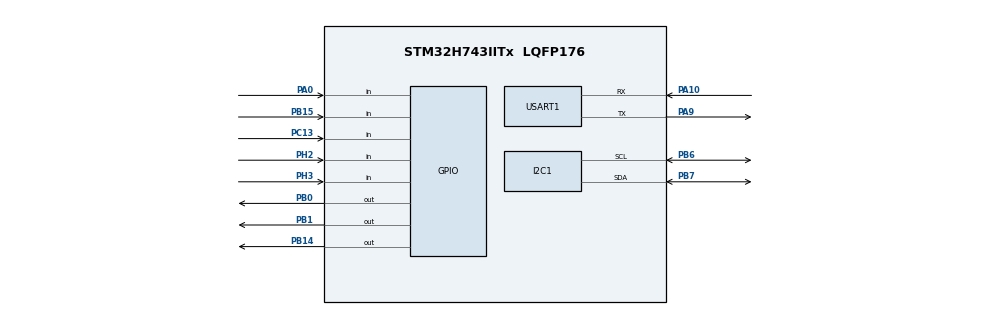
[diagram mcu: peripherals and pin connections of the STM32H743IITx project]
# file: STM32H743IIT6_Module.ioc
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Dma.Request0=USART1_RX
Dma.USART1_RX.0.Direction=DMA_PERIPH_TO_MEMORY
Dma.USART1_RX.0.EventEnable=DISABLE
Dma.USART1_RX.0.FIFOMode=DMA_FIFOMODE_DISABLE
Dma.USART1_RX.0.Instance=DMA1_Stream0
Dma.USART1_RX.0.MemDataAlignment=DMA_MDATAALIGN_BYTE
Dma.USART1_RX.0.MemInc=DMA_MINC_ENABLE
Dma.USART1_RX.0.Mode=DMA_NORMAL
Dma.USART1_RX.0.PeriphDataAlignment=DMA_PDATAALIGN_BYTE
Dma.USART1_RX.0.PeriphInc=DMA_PINC_DISABLE
Dma.USART1_RX.0.Polarity=HAL_DMAMUX_REQ_GEN_RISING
Dma.USART1_RX.0.Priority=DMA_PRIORITY_LOW
Dma.USART1_RX.0.RequestNumber=1
Dma.USART1_RX.0.SignalID=NONE
Dma.USART1_RX.0.SyncEnable=DISABLE
Dma.USART1_RX.0.SyncPolarity=HAL_DMAMUX_SYNC_NO_EVENT
Dma.USART1_RX.0.SyncRequestNumber=1
Dma.USART1_RX.0.SyncSignalID=NONE
I2C1.Timing=0x307075B1
Mcu.Family=STM32H7
Mcu.Name=STM32H743IITx
Mcu.Package=LQFP176
NVIC.DMA1_Stream0_IRQn=true\:0\:0\:false\:false\:true\:false\:true\:true
NVIC.PriorityGroup=NVIC_PRIORITYGROUP_4
NVIC.TIM6_DAC_IRQn=true\:0\:0\:false\:false\:true\:true\:true\:true
NVIC.USART1_IRQn=true\:0\:0\:false\:false\:true\:true\:true\:true
PA0.GPIO_PuPd=GPIO_PULLDOWN
PA0.Signal=GPIO_Input
PA10.Mode=Asynchronous
PA10.Signal=USART1_RX
PA9.Mode=Asynchronous
PA9.Signal=USART1_TX
PB0.Signal=GPIO_Output
PB1.Signal=GPIO_Output
PB14.GPIO_PuPd=GPIO_PULLDOWN
PB14.Signal=GPIO_Output
PB15.GPIO_PuPd=GPIO_PULLDOWN
PB15.Signal=GPIO_Input
PB6.Mode=I2C
PB6.Signal=I2C1_SCL
PB7.Mode=I2C
PB7.Signal=I2C1_SDA
PC13.GPIO_PuPd=GPIO_PULLUP
PC13.Signal=GPIO_Input
PC14-OSC32_IN\ (OSC32_IN).Mode=LSE-External-Oscillator
PC14-OSC32_IN\ (OSC32_IN).Signal=RCC_OSC32_IN
PC15-OSC32_OUT\ (OSC32_OUT).Mode=LSE-External-Oscillator
PC15-OSC32_OUT\ (OSC32_OUT).Signal=RCC_OSC32_OUT
PH0-OSC_IN\ (PH0).Mode=HSE-External-Oscillator
PH0-OSC_IN\ (PH0).Signal=RCC_OSC_IN
PH1-OSC_OUT\ (PH1).Mode=HSE-External-Oscillator
PH1-OSC_OUT\ (PH1).Signal=RCC_OSC_OUT
PH2.GPIO_PuPd=GPIO_PULLUP
PH2.Signal=GPIO_Input
PH3.GPIO_PuPd=GPIO_PULLUP
PH3.Signal=GPIO_Input
ProjectManager.HeapSize=0x200
ProjectManager.StackSize=0x400
ProjectManager.TargetToolchain=MDK-ARM V5.32
RCC.ADCFreq_Value=129000000
RCC.APB1Freq_Value=120000000
RCC.APB2Freq_Value=120000000
RCC.APB3Freq_Value=120000000
RCC.APB4Freq_Value=120000000
RCC.CortexFreq_Value=480000000
RCC.D1PPRE=RCC_APB3_DIV2
RCC.D2PPRE1=RCC_APB1_DIV2
RCC.D2PPRE2=RCC_APB2_DIV2
RCC.D3PPRE=RCC_APB4_DIV2
RCC.DIVM1=4
RCC.DIVN1=60
RCC.HCLKFreq_Value=240000000
RCC.HPRE=RCC_HCLK_DIV2
RCC.HSE_VALUE=25000000
RCC.PLL2FRACN=0
RCC.PLL3FRACN=0
RCC.PLLFRACN=0
RCC.PWR_Regulator_Voltage_Scale=PWR_REGULATOR_VOLTAGE_SCALE0
RCC.SYSCLKFreq_VALUE=480000000
RCC.SYSCLKSource=RCC_SYSCLKSOURCE_PLLCLK
RCC.USBFreq_Value=480000000
TIM6.AutoReloadPreload=TIM_AUTORELOAD_PRELOAD_ENABLE
TIM6.Period=100
TIM6.Prescaler=2400
TIM7.AutoReloadPreload=TIM_AUTORELOAD_PRELOAD_DISABLE
TIM7.Period=24000-1
TIM7.Prescaler=10000-1
USART1.VirtualMode-Asynchronous=VM_ASYNC
VP_MEMORYMAP_VS_MEMORYMAP.Mode=CurAppReg
VP_TIM6_VS_ClockSourceINT.Mode=Enable_Timer
VP_TIM7_VS_ClockSourceINT.Mode=Enable_Timer
board=custom

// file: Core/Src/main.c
/* USER CODE BEGIN Header */
/**
  ******************************************************************************
  * @file           : main.c
  * @brief          : Main program body
  ******************************************************************************
  * @attention
  *
  * <h2><center>&copy; Copyright (c) 2026 STMicroelectronics.
  * All rights reserved.</center></h2>
  *
  * This software component is licensed by ST under BSD 3-Clause license,
  * the "License"; You may not use this file except in compliance with the
  * License. You may obtain a copy of the License at:
  *                        opensource.org/licenses/BSD-3-Clause
  *
  ******************************************************************************
  */
/* USER CODE END Header */
#include "main.h"
#include "dma.h"
#include "i2c.h"
#include "tim.h"
#include "usart.h"
#include "gpio.h"

/* USER CODE BEGIN Includes */
#include "bsp.h"
/* USER CODE END Includes */

void SystemClock_Config(void);

int main(void)
{

  /* MCU Configuration--------------------------------------------------------*/

  /* Reset of all peripherals, Initializes the Flash interface and the Systick. */
  HAL_Init();

  /* Configure the system clock */
  SystemClock_Config();

  /* Initialize all configured peripherals */
  MX_GPIO_Init();
  MX_DMA_Init();
  MX_TIM6_Init();
  MX_USART1_UART_Init();
  MX_I2C1_Init();
  MX_TIM7_Init();
  /* USER CODE BEGIN 2 */
  Sys_Init();
  /* USER CODE END 2 */

  /* Infinite loop */
  while (1)
  {

    /* USER CODE BEGIN 3 */
    Sys_Run();
  }
  /* USER CODE END 3 */
}

void SystemClock_Config(void)
{
  RCC_OscInitTypeDef RCC_OscInitStruct = {0};
  RCC_ClkInitTypeDef RCC_ClkInitStruct = {0};

  /** Supply configuration update enable
  */
  HAL_PWREx_ConfigSupply(PWR_LDO_SUPPLY);

  /** Configure the main internal regulator output voltage
  */
  __HAL_PWR_VOLTAGESCALING_CONFIG(PWR_REGULATOR_VOLTAGE_SCALE0);

  while(!__HAL_PWR_GET_FLAG(PWR_FLAG_VOSRDY)) {}

  /** Initializes the RCC Oscillators according to the specified parameters
  * in the RCC_OscInitTypeDef structure.
  */
  RCC_OscInitStruct.OscillatorType = RCC_OSCILLATORTYPE_HSI;
  RCC_OscInitStruct.HSIState = RCC_HSI_DIV1;
  RCC_OscInitStruct.HSICalibrationValue = RCC_HSICALIBRATION_DEFAULT;
  RCC_OscInitStruct.PLL.PLLState = RCC_PLL_ON;
  RCC_OscInitStruct.PLL.PLLSource = RCC_PLLSOURCE_HSI;
  RCC_OscInitStruct.PLL.PLLM = 4;
  RCC_OscInitStruct.PLL.PLLN = 60;
  RCC_OscInitStruct.PLL.PLLP = 2;
  RCC_OscInitStruct.PLL.PLLQ = 2;
  RCC_OscInitStruct.PLL.PLLR = 2;
  RCC_OscInitStruct.PLL.PLLRGE = RCC_PLL1VCIRANGE_3;
  RCC_OscInitStruct.PLL.PLLVCOSEL = RCC_PLL1VCOWIDE;
  RCC_OscInitStruct.PLL.PLLFRACN = 0;
  if (HAL_RCC_OscConfig(&RCC_OscInitStruct) != HAL_OK)
  {
    Error_Handler();
  }

  /** Initializes the CPU, AHB and APB buses clocks
  */
  RCC_ClkInitStruct.ClockType = RCC_CLOCKTYPE_HCLK|RCC_CLOCKTYPE_SYSCLK
                              |RCC_CLOCKTYPE_PCLK1|RCC_CLOCKTYPE_PCLK2
                              |RCC_CLOCKTYPE_D3PCLK1|RCC_CLOCKTYPE_D1PCLK1;
  RCC_ClkInitStruct.SYSCLKSource = RCC_SYSCLKSOURCE_PLLCLK;
  RCC_ClkInitStruct.SYSCLKDivider = RCC_SYSCLK_DIV1;
  RCC_ClkInitStruct.AHBCLKDivider = RCC_HCLK_DIV2;
  RCC_ClkInitStruct.APB3CLKDivider = RCC_APB3_DIV2;
  RCC_ClkInitStruct.APB1CLKDivider = RCC_APB1_DIV2;
  RCC_ClkInitStruct.APB2CLKDivider = RCC_APB2_DIV2;
  RCC_ClkInitStruct.APB4CLKDivider = RCC_APB4_DIV2;

  if (HAL_RCC_ClockConfig(&RCC_ClkInitStruct, FLASH_LATENCY_4) != HAL_OK)
  {
    Error_Handler();
  }
}

void Error_Handler(void)
{
  __disable_irq();
  while (1)
  {
  }
}
